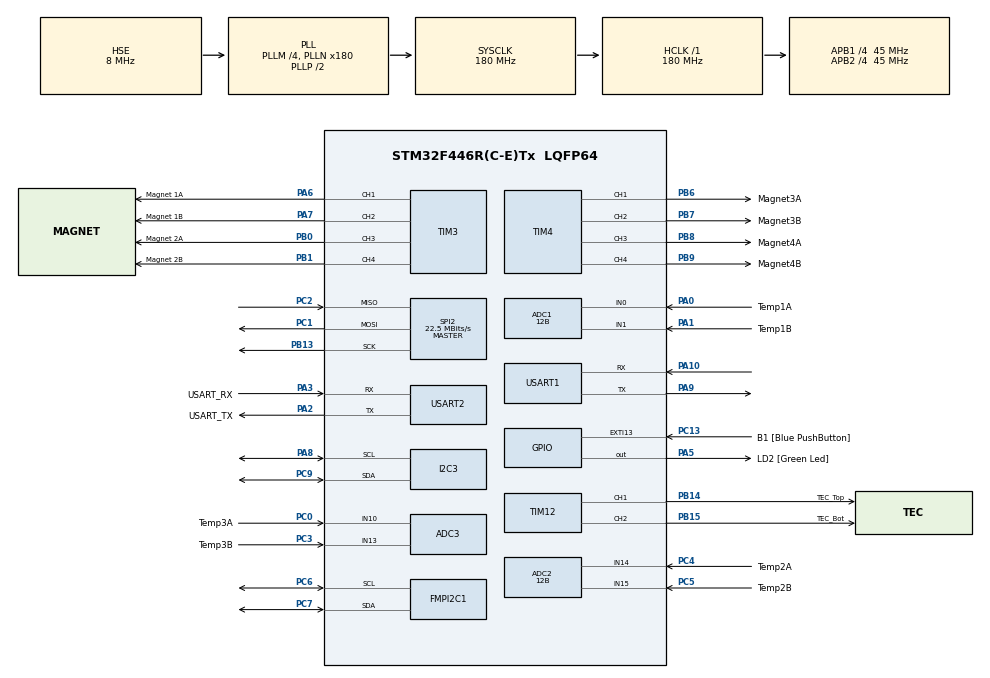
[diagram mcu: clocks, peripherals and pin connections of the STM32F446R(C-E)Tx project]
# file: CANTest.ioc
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ADC1.Channel-0\#ChannelRegularConversion=ADC_CHANNEL_0
ADC1.Channel-1\#ChannelRegularConversion=ADC_CHANNEL_1
ADC1.Channel-2\#ChannelInjectedConversion=ADC_CHANNEL_0
ADC1.Channel-3\#ChannelInjectedConversion=ADC_CHANNEL_0
ADC1.ClockPrescaler=ADC_CLOCK_SYNC_PCLK_DIV6
ADC1.ContinuousConvMode=ENABLE
ADC1.DMAContinuousRequests=ENABLE
ADC1.DataAlign=ADC_DATAALIGN_RIGHT
ADC1.DiscontinuousConvMode=DISABLE
ADC1.EOCSelection=ADC_EOC_SEQ_CONV
ADC1.EnableAnalogWatchDog=false
ADC1.ExternalTrigConv=ADC_SOFTWARE_START
ADC1.ExternalTrigConvEdge=ADC_EXTERNALTRIGCONVEDGE_NONE
ADC1.InjNumberOfConversion=0
ADC1.InjectedOffset-2\#ChannelInjectedConversion=0
ADC1.InjectedOffset-3\#ChannelInjectedConversion=0
ADC1.NbrOfConversion=2
ADC1.NbrOfConversionFlag=1
ADC1.Rank-0\#ChannelRegularConversion=1
ADC1.Rank-1\#ChannelRegularConversion=2
ADC1.Rank-2\#ChannelInjectedConversion=1
ADC1.Rank-3\#ChannelInjectedConversion=2
ADC1.Resolution=ADC_RESOLUTION_12B
ADC1.SamplingTime-0\#ChannelRegularConversion=ADC_SAMPLETIME_15CYCLES
ADC1.SamplingTime-1\#ChannelRegularConversion=ADC_SAMPLETIME_15CYCLES
ADC1.SamplingTime-2\#ChannelInjectedConversion=ADC_SAMPLETIME_3CYCLES
ADC1.SamplingTime-3\#ChannelInjectedConversion=ADC_SAMPLETIME_3CYCLES
ADC1.ScanConvMode=ENABLE
ADC1.master=1
ADC2.Channel-0\#ChannelRegularConversion=ADC_CHANNEL_15
ADC2.ClockPrescaler=ADC_CLOCK_SYNC_PCLK_DIV6
ADC2.ContinuousConvMode=DISABLE
ADC2.DMAContinuousRequests=DISABLE
ADC2.DataAlign=ADC_DATAALIGN_RIGHT
ADC2.DiscontinuousConvMode=DISABLE
ADC2.EOCSelection=ADC_EOC_SINGLE_CONV
ADC2.EnableAnalogWatchDog=false
ADC2.ExternalTrigConv=ADC_SOFTWARE_START
ADC2.ExternalTrigConvEdge=ADC_EXTERNALTRIGCONVEDGE_NONE
ADC2.InjNumberOfConversion=0
ADC2.NbrOfConversion=1
ADC2.NbrOfConversionFlag=1
ADC2.Rank-0\#ChannelRegularConversion=1
ADC2.Resolution=ADC_RESOLUTION_12B
ADC2.SamplingTime-0\#ChannelRegularConversion=ADC_SAMPLETIME_3CYCLES
ADC2.ScanConvMode=DISABLE
ADC3.Channel-4\#ChannelRegularConversion=ADC_CHANNEL_10
ADC3.ClockPrescaler=ADC_CLOCK_SYNC_PCLK_DIV6
ADC3.NbrOfConversionFlag=1
ADC3.Rank-4\#ChannelRegularConversion=1
ADC3.SamplingTime-4\#ChannelRegularConversion=ADC_SAMPLETIME_3CYCLES
Dma.ADC1.0.Direction=DMA_PERIPH_TO_MEMORY
Dma.ADC1.0.FIFOMode=DMA_FIFOMODE_DISABLE
Dma.ADC1.0.Instance=DMA2_Stream0
Dma.ADC1.0.MemDataAlignment=DMA_MDATAALIGN_HALFWORD
Dma.ADC1.0.MemInc=DMA_MINC_ENABLE
Dma.ADC1.0.Mode=DMA_CIRCULAR
Dma.ADC1.0.PeriphDataAlignment=DMA_PDATAALIGN_HALFWORD
Dma.ADC1.0.PeriphInc=DMA_PINC_DISABLE
Dma.ADC1.0.Priority=DMA_PRIORITY_VERY_HIGH
Dma.Request0=ADC1
FREERTOS.Tasks01=defaultTask,0,128,StartDefaultTask,Default,NULL,Dynamic,NULL,NULL;dataLogTask,-3,128,StartDataLogTask,Default,NULL,Dynamic,NULL,NULL;tempSenseTask,-3,128,StartTempSenseTask,Default,NULL,Dynamic,NULL,NULL;magnetSetTask,-3,128,StartMagnetSetTask,Default,NULL,Dynamic,NULL,NULL
FREERTOS.configCHECK_FOR_STACK_OVERFLOW=2
FREERTOS.configGENERATE_RUN_TIME_STATS=1
FREERTOS.configUSE_TIMERS=1
Mcu.Family=STM32F4
Mcu.Name=STM32F446R(C-E)Tx
Mcu.Package=LQFP64
NVIC.DMA2_Stream0_IRQn=true\:5\:0\:false\:false\:true\:true\:false
NVIC.PriorityGroup=NVIC_PRIORITYGROUP_4
PA0-WKUP.GPIO_Label=Temp1A
PA0-WKUP.Signal=ADCx_IN0
PA1.GPIO_Label=Temp1B
PA1.Signal=ADCx_IN1
PA10.Mode=Asynchronous
PA10.Signal=USART1_RX
PA13.GPIO_Label=TMS
PA13.Signal=SYS_JTMS-SWDIO
PA14.GPIO_Label=TCK
PA14.Signal=SYS_JTCK-SWCLK
PA2.GPIO_Label=USART_TX
PA2.Mode=Asynchronous
PA2.Signal=USART2_TX
PA3.GPIO_Label=USART_RX
PA3.Mode=Asynchronous
PA3.Signal=USART2_RX
PA5.GPIO_Label=LD2 [Green Led]
PA5.Signal=GPIO_Output
PA6.GPIO_Label=Magnet 1A
PA6.Signal=S_TIM3_CH1
PA7.GPIO_Label=Magnet 1B
PA7.Signal=S_TIM3_CH2
PA8.Mode=I2C
PA8.Signal=I2C3_SCL
PA9.Mode=Asynchronous
PA9.Signal=USART1_TX
PB0.GPIO_Label=Magnet 2A
PB0.Signal=S_TIM3_CH3
PB1.GPIO_Label=Magnet 2B
PB1.Signal=S_TIM3_CH4
PB13.Mode=Full_Duplex_Master
PB13.Signal=SPI2_SCK
PB14.GPIO_Label=TEC_Top
PB14.Signal=S_TIM12_CH1
PB15.GPIO_Label=TEC_Bot
PB15.Signal=S_TIM12_CH2
PB3.GPIO_Label=SWO
PB3.Signal=SYS_JTDO-SWO
PB6.GPIO_Label=Magnet3A
PB6.Signal=S_TIM4_CH1
PB7.GPIO_Label=Magnet3B
PB7.GPIO_Speed=GPIO_SPEED_FREQ_LOW
PB7.Signal=S_TIM4_CH2
PB8.GPIO_Label=Magnet4A
PB8.GPIO_Speed=GPIO_SPEED_FREQ_LOW
PB8.Signal=S_TIM4_CH3
PB9.GPIO_Label=Magnet4B
PB9.GPIO_Speed=GPIO_SPEED_FREQ_LOW
PB9.Signal=S_TIM4_CH4
PC0.GPIO_Label=Temp3A
PC0.Signal=ADCx_IN10
PC1.Mode=Full_Duplex_Master
PC1.Signal=SPI2_MOSI
PC13.GPIO_Label=B1 [Blue PushButton]
PC13.GPIO_ModeDefaultEXTI=GPIO_MODE_EVT_RISING
PC13.Signal=GPXTI13
PC14-OSC32_IN.Mode=LSE-External-Oscillator
PC14-OSC32_IN.Signal=RCC_OSC32_IN
PC15-OSC32_OUT.Mode=LSE-External-Oscillator
PC15-OSC32_OUT.Signal=RCC_OSC32_OUT
PC2.Mode=Full_Duplex_Master
PC2.Signal=SPI2_MISO
PC3.GPIO_Label=Temp3B
PC3.Signal=ADCx_IN13
PC4.GPIO_Label=Temp2A
PC4.Signal=ADCx_IN14
PC5.GPIO_Label=Temp2B
PC5.Signal=ADCx_IN15
PC6.Mode=I2C
PC6.Signal=FMPI2C1_SCL
PC7.Mode=I2C
PC7.Signal=FMPI2C1_SDA
PC9.Mode=I2C
PC9.Signal=I2C3_SDA
PH0-OSC_IN.Mode=HSE-External-Clock-Source
PH0-OSC_IN.Signal=RCC_OSC_IN
PH1-OSC_OUT.Mode=HSE-External-Clock-Source
PH1-OSC_OUT.Signal=RCC_OSC_OUT
ProjectManager.HeapSize=0x200
ProjectManager.StackSize=0x400
ProjectManager.TargetToolchain=SW4STM32
RCC.AHBFreq_Value=180000000
RCC.APB1CLKDivider=RCC_HCLK_DIV4
RCC.APB1Freq_Value=45000000
RCC.APB1TimFreq_Value=90000000
RCC.APB2CLKDivider=RCC_HCLK_DIV4
RCC.APB2Freq_Value=45000000
RCC.APB2TimFreq_Value=90000000
RCC.CortexFreq_Value=180000000
RCC.FLatency-AdvancedSettings=FLASH_LATENCY_5
RCC.HCLKFreq_Value=180000000
RCC.HSE_VALUE=8000000
RCC.HSI_VALUE=16000000
RCC.PLLM=4
RCC.PLLN=180
RCC.PLLSourceVirtual=RCC_PLLSOURCE_HSE
RCC.RCC_RTC_Clock_SourceVirtual=RCC_RTCCLKSOURCE_LSE
RCC.SYSCLKFreq_VALUE=180000000
RCC.SYSCLKSource=RCC_SYSCLKSOURCE_PLLCLK
RCC.USBFreq_Value=180000000
RCC.VCOOutputFreq_Value=360000000
RTC.Format=RTC_FORMAT_BIN
SH.ADCx_IN0.0=ADC1_IN0,IN0
SH.ADCx_IN1.0=ADC1_IN1,IN1
SH.ADCx_IN10.0=ADC3_IN10,IN10
SH.ADCx_IN13.0=ADC3_IN13,IN13
SH.ADCx_IN14.0=ADC2_IN14,IN14
SH.ADCx_IN15.0=ADC2_IN15,IN15
SH.S_TIM12_CH1.0=TIM12_CH1,PWM Generation1 CH1
SH.S_TIM12_CH2.0=TIM12_CH2,PWM Generation2 CH2
SH.S_TIM3_CH1.0=TIM3_CH1,Output Compare1 CH1
SH.S_TIM3_CH2.0=TIM3_CH2,Output Compare2 CH2
SH.S_TIM3_CH3.0=TIM3_CH3,Output Compare3 CH3
SH.S_TIM3_CH4.0=TIM3_CH4,Output Compare4 CH4
SH.S_TIM4_CH1.0=TIM4_CH1,Output Compare1 CH1
SH.S_TIM4_CH2.0=TIM4_CH2,Output Compare2 CH2
SH.S_TIM4_CH3.0=TIM4_CH3,Output Compare3 CH3
SH.S_TIM4_CH4.0=TIM4_CH4,Output Compare4 CH4
SPI2.BaudRatePrescaler=SPI_BAUDRATEPRESCALER_2
SPI2.CalculateBaudRate=22.5 MBits/s
SPI2.Direction=SPI_DIRECTION_2LINES
SPI2.Mode=SPI_MODE_MASTER
SPI2.VirtualType=VM_MASTER
TIM12.Channel-PWM\ Generation1\ CH1=TIM_CHANNEL_1
TIM12.Channel-PWM\ Generation2\ CH2=TIM_CHANNEL_2
TIM3.Channel-Output\ Compare1\ CH1=TIM_CHANNEL_1
TIM3.Channel-Output\ Compare2\ CH2=TIM_CHANNEL_2
TIM3.Channel-Output\ Compare3\ CH3=TIM_CHANNEL_3
TIM3.Channel-Output\ Compare4\ CH4=TIM_CHANNEL_4
TIM3.OCMode_1=TIM_OCMODE_ACTIVE
TIM3.OCMode_2=TIM_OCMODE_ACTIVE
TIM3.OCMode_3=TIM_OCMODE_ACTIVE
TIM3.OCMode_4=TIM_OCMODE_ACTIVE
TIM3.TIM_MasterSlaveMode=TIM_MASTERSLAVEMODE_ENABLE
TIM4.Channel-Output\ Compare1\ CH1=TIM_CHANNEL_1
TIM4.Channel-Output\ Compare2\ CH2=TIM_CHANNEL_2
TIM4.Channel-Output\ Compare3\ CH3=TIM_CHANNEL_3
TIM4.Channel-Output\ Compare4\ CH4=TIM_CHANNEL_4
TIM4.OCMode_1=TIM_OCMODE_ACTIVE
TIM4.OCMode_2=TIM_OCMODE_ACTIVE
TIM4.OCMode_3=TIM_OCMODE_ACTIVE
TIM4.OCMode_4=TIM_OCMODE_ACTIVE
TIM4.TIM_MasterSlaveMode=TIM_MASTERSLAVEMODE_ENABLE
USART1.VirtualMode=VM_ASYNC
USART2.VirtualMode=VM_ASYNC
VP_FREERTOS_VS_ENABLE.Mode=Enabled
VP_RTC_VS_RTC_Activate.Mode=RTC_Enabled
VP_RTC_VS_RTC_Calendar.Mode=RTC_Calendar
VP_WWDG_VS_WWDG.Mode=WWDG_Activate
board=NUCLEO-F446RE

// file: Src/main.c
/**
  ******************************************************************************
  * File Name          : main.c
  * Description        : Main program body
  ******************************************************************************
  * This notice applies to any and all portions of this file
  * that are not between comment pairs USER CODE BEGIN and
  * USER CODE END. Other portions of this file, whether
  * inserted by the user or by software development tools
  * are owned by their respective copyright owners.
  *
  * Copyright (c) 2017 STMicroelectronics International N.V.
  * All rights reserved.
  *
  * Redistribution and use in source and binary forms, with or without
  * modification, are permitted, provided that the following conditions are met:
  *
  * 1. Redistribution of source code must retain the above copyright notice,
  *    this list of conditions and the following disclaimer.
  * 2. Redistributions in binary form must reproduce the above copyright notice,
  *    this list of conditions and the following disclaimer in the documentation
  *    and/or other materials provided with the distribution.
  * 3. Neither the name of STMicroelectronics nor the names of other
  *    contributors to this software may be used to endorse or promote products
  *    derived from this software without specific written permission.
  * 4. This software, including modifications and/or derivative works of this
  *    software, must execute solely and exclusively on microcontroller or
  *    microprocessor devices manufactured by or for STMicroelectronics.
  * 5. Redistribution and use of this software other than as permitted under
  *    this license is void and will automatically terminate your rights under
  *    this license.
  *
  * THIS SOFTWARE IS PROVIDED BY STMICROELECTRONICS AND CONTRIBUTORS "AS IS"
  * AND ANY EXPRESS, IMPLIED OR STATUTORY WARRANTIES, INCLUDING, BUT NOT
  * LIMITED TO, THE IMPLIED WARRANTIES OF MERCHANTABILITY, FITNESS FOR A
  * PARTICULAR PURPOSE AND NON-INFRINGEMENT OF THIRD PARTY INTELLECTUAL PROPERTY
  * RIGHTS ARE DISCLAIMED TO THE FULLEST EXTENT PERMITTED BY LAW. IN NO EVENT
  * SHALL STMICROELECTRONICS OR CONTRIBUTORS BE LIABLE FOR ANY DIRECT, INDIRECT,
  * INCIDENTAL, SPECIAL, EXEMPLARY, OR CONSEQUENTIAL DAMAGES (INCLUDING, BUT NOT
  * LIMITED TO, PROCUREMENT OF SUBSTITUTE GOODS OR SERVICES; LOSS OF USE, DATA,
  * OR PROFITS; OR BUSINESS INTERRUPTION) HOWEVER CAUSED AND ON ANY THEORY OF
  * LIABILITY, WHETHER IN CONTRACT, STRICT LIABILITY, OR TORT (INCLUDING
  * NEGLIGENCE OR OTHERWISE) ARISING IN ANY WAY OUT OF THE USE OF THIS SOFTWARE,
  * EVEN IF ADVISED OF THE POSSIBILITY OF SUCH DAMAGE.
  *
  ******************************************************************************
  */

#include "main.h"
#include "stm32f4xx_hal.h"
#include "cmsis_os.h"

ADC_HandleTypeDef hadc1;
ADC_HandleTypeDef hadc2;
ADC_HandleTypeDef hadc3;

FMPI2C_HandleTypeDef hfmpi2c1;

I2C_HandleTypeDef hi2c3;

RTC_HandleTypeDef hrtc;
RTC_TimeTypeDef sTime;
RTC_DateTypeDef sDate;

SPI_HandleTypeDef hspi2;

TIM_HandleTypeDef htim3;
TIM_HandleTypeDef htim4;
TIM_HandleTypeDef htim12;

UART_HandleTypeDef huart1;
UART_HandleTypeDef huart2;

WWDG_HandleTypeDef hwwdg;

osThreadId defaultTaskHandle;
osThreadId dataLogTaskHandle;
osThreadId tempSenseTaskHandle;
osThreadId magnetSetTaskHandle;

/* USER CODE BEGIN PV */
/* Private variables ---------------------------------------------------------*/

/* USER CODE END PV */

void SystemClock_Config(void);
static void MX_GPIO_Init(void);
static void MX_ADC1_Init(void);
static void MX_ADC2_Init(void);
static void MX_ADC3_Init(void);
static void MX_FMPI2C1_Init(void);
static void MX_I2C3_Init(void);
static void MX_RTC_Init(void);
static void MX_SPI2_Init(void);
static void MX_TIM3_Init(void);
static void MX_TIM4_Init(void);
static void MX_TIM12_Init(void);
static void MX_USART1_UART_Init(void);
static void MX_USART2_UART_Init(void);
static void MX_WWDG_Init(void);
void StartDefaultTask(void const * argument);
void StartDataLogTask(void const * argument);
void StartTempSenseTask(void const * argument);
void StartMagnetSetTask(void const * argument);

void HAL_TIM_MspPostInit(TIM_HandleTypeDef *htim);

/* USER CODE BEGIN PFP */
/* Private function prototypes -----------------------------------------------*/

/* USER CODE END PFP */

int main(void)
{

  /* USER CODE BEGIN 1 */
  int i_hello_user;
  /* USER CODE END 1 */

  /* MCU Configuration----------------------------------------------------------*/

  /* Reset of all peripherals, Initializes the Flash interface and the Systick. */
  HAL_Init();

  /* Configure the system clock */
  SystemClock_Config();

  /* Initialize all configured peripherals */
  MX_GPIO_Init();
  MX_ADC1_Init();
  MX_ADC2_Init();
  MX_ADC3_Init();
  MX_FMPI2C1_Init();
  MX_I2C3_Init();
  MX_RTC_Init();
  MX_SPI2_Init();
  MX_TIM3_Init();
  MX_TIM4_Init();
  MX_TIM12_Init();
  MX_USART1_UART_Init();
  MX_USART2_UART_Init();
  MX_WWDG_Init();

  /* Create the thread(s) */
  /* definition and creation of defaultTask */
  osThreadDef(defaultTask, StartDefaultTask, osPriorityNormal, 0, 128);
  defaultTaskHandle = osThreadCreate(osThread(defaultTask), NULL);

  /* definition and creation of dataLogTask */
  osThreadDef(dataLogTask, StartDataLogTask, osPriorityIdle, 0, 128);
  dataLogTaskHandle = osThreadCreate(osThread(dataLogTask), NULL);

  /* definition and creation of tempSenseTask */
  osThreadDef(tempSenseTask, StartTempSenseTask, osPriorityIdle, 0, 128);
  tempSenseTaskHandle = osThreadCreate(osThread(tempSenseTask), NULL);

  /* definition and creation of magnetSetTask */
  osThreadDef(magnetSetTask, StartMagnetSetTask, osPriorityIdle, 0, 128);
  magnetSetTaskHandle = osThreadCreate(osThread(magnetSetTask), NULL);

  /* Start scheduler */
  osKernelStart();

  /* We should never get here as control is now taken by the scheduler */

  /* Infinite loop */
  while (1)
  {

  }

}

/** System Clock Configuration
*/
void SystemClock_Config(void)
{

  RCC_OscInitTypeDef RCC_OscInitStruct;
  RCC_ClkInitTypeDef RCC_ClkInitStruct;
  RCC_PeriphCLKInitTypeDef PeriphClkInitStruct;

    /**Configure the main internal regulator output voltage
    */
  __HAL_RCC_PWR_CLK_ENABLE();

  __HAL_PWR_VOLTAGESCALING_CONFIG(PWR_REGULATOR_VOLTAGE_SCALE1);

    /**Initializes the CPU, AHB and APB busses clocks
    */
  RCC_OscInitStruct.OscillatorType = RCC_OSCILLATORTYPE_HSE|RCC_OSCILLATORTYPE_LSE;
  RCC_OscInitStruct.HSEState = RCC_HSE_BYPASS;
  RCC_OscInitStruct.LSEState = RCC_LSE_ON;
  RCC_OscInitStruct.PLL.PLLState = RCC_PLL_ON;
  RCC_OscInitStruct.PLL.PLLSource = RCC_PLLSOURCE_HSE;
  RCC_OscInitStruct.PLL.PLLM = 4;
  RCC_OscInitStruct.PLL.PLLN = 180;
  RCC_OscInitStruct.PLL.PLLP = RCC_PLLP_DIV2;
  RCC_OscInitStruct.PLL.PLLQ = 2;
  RCC_OscInitStruct.PLL.PLLR = 2;
  if (HAL_RCC_OscConfig(&RCC_OscInitStruct) != HAL_OK)
  {
    _Error_Handler(__FILE__, __LINE__);
  }

    /**Activate the Over-Drive mode
    */
  if (HAL_PWREx_EnableOverDrive() != HAL_OK)
  {
    _Error_Handler(__FILE__, __LINE__);
  }

    /**Initializes the CPU, AHB and APB busses clocks
    */
  RCC_ClkInitStruct.ClockType = RCC_CLOCKTYPE_HCLK|RCC_CLOCKTYPE_SYSCLK
                              |RCC_CLOCKTYPE_PCLK1|RCC_CLOCKTYPE_PCLK2;
  RCC_ClkInitStruct.SYSCLKSource = RCC_SYSCLKSOURCE_PLLCLK;
  RCC_ClkInitStruct.AHBCLKDivider = RCC_SYSCLK_DIV1;
  RCC_ClkInitStruct.APB1CLKDivider = RCC_HCLK_DIV4;
  RCC_ClkInitStruct.APB2CLKDivider = RCC_HCLK_DIV4;

  if (HAL_RCC_ClockConfig(&RCC_ClkInitStruct, FLASH_LATENCY_5) != HAL_OK)
  {
    _Error_Handler(__FILE__, __LINE__);
  }

  PeriphClkInitStruct.PeriphClockSelection = RCC_PERIPHCLK_RTC|RCC_PERIPHCLK_FMPI2C1;
  PeriphClkInitStruct.RTCClockSelection = RCC_RTCCLKSOURCE_LSE;
  PeriphClkInitStruct.Fmpi2c1ClockSelection = RCC_FMPI2C1CLKSOURCE_APB;
  if (HAL_RCCEx_PeriphCLKConfig(&PeriphClkInitStruct) != HAL_OK)
  {
    _Error_Handler(__FILE__, __LINE__);
  }

    /**Configure the Systick interrupt time
    */
  HAL_SYSTICK_Config(HAL_RCC_GetHCLKFreq()/1000);

    /**Configure the Systick
    */
  HAL_SYSTICK_CLKSourceConfig(SYSTICK_CLKSOURCE_HCLK);

  /* SysTick_IRQn interrupt configuration */
  HAL_NVIC_SetPriority(SysTick_IRQn, 15, 0);
}

/* ADC1 init function */
static void MX_ADC1_Init(void)
{

  ADC_ChannelConfTypeDef sConfig;

    /**Configure the global features of the ADC (Clock, Resolution, Data Alignment and number of conversion)
    */
  hadc1.Instance = ADC1;
  hadc1.Init.ClockPrescaler = ADC_CLOCK_SYNC_PCLK_DIV2;
  hadc1.Init.Resolution = ADC_RESOLUTION_12B;
  hadc1.Init.ScanConvMode = DISABLE;
  hadc1.Init.ContinuousConvMode = DISABLE;
  hadc1.Init.DiscontinuousConvMode = DISABLE;
  hadc1.Init.ExternalTrigConvEdge = ADC_EXTERNALTRIGCONVEDGE_NONE;
  hadc1.Init.ExternalTrigConv = ADC_SOFTWARE_START;
  hadc1.Init.DataAlign = ADC_DATAALIGN_RIGHT;
  hadc1.Init.NbrOfConversion = 1;
  hadc1.Init.DMAContinuousRequests = DISABLE;
  hadc1.Init.EOCSelection = ADC_EOC_SINGLE_CONV;
  if (HAL_ADC_Init(&hadc1) != HAL_OK)
  {
    _Error_Handler(__FILE__, __LINE__);
  }

    /**Configure for the selected ADC regular channel its corresponding rank in the sequencer and its sample time.
    */
  sConfig.Channel = ADC_CHANNEL_0;
  sConfig.Rank = 1;
  sConfig.SamplingTime = ADC_SAMPLETIME_3CYCLES;
  if (HAL_ADC_ConfigChannel(&hadc1, &sConfig) != HAL_OK)
  {
    _Error_Handler(__FILE__, __LINE__);
  }

}

/* ADC2 init function */
static void MX_ADC2_Init(void)
{

  ADC_ChannelConfTypeDef sConfig;

    /**Configure the global features of the ADC (Clock, Resolution, Data Alignment and number of conversion)
    */
  hadc2.Instance = ADC2;
  hadc2.Init.ClockPrescaler = ADC_CLOCK_SYNC_PCLK_DIV2;
  hadc2.Init.Resolution = ADC_RESOLUTION_12B;
  hadc2.Init.ScanConvMode = DISABLE;
  hadc2.Init.ContinuousConvMode = DISABLE;
  hadc2.Init.DiscontinuousConvMode = DISABLE;
  hadc2.Init.ExternalTrigConvEdge = ADC_EXTERNALTRIGCONVEDGE_NONE;
  hadc2.Init.ExternalTrigConv = ADC_SOFTWARE_START;
  hadc2.Init.DataAlign = ADC_DATAALIGN_RIGHT;
  hadc2.Init.NbrOfConversion = 1;
  hadc2.Init.DMAContinuousRequests = DISABLE;
  hadc2.Init.EOCSelection = ADC_EOC_SINGLE_CONV;
  if (HAL_ADC_Init(&hadc2) != HAL_OK)
  {
    _Error_Handler(__FILE__, __LINE__);
  }

    /**Configure for the selected ADC regular channel its corresponding rank in the sequencer and its sample time.
    */
  sConfig.Channel = ADC_CHANNEL_15;
  sConfig.Rank = 1;
  sConfig.SamplingTime = ADC_SAMPLETIME_3CYCLES;
  if (HAL_ADC_ConfigChannel(&hadc2, &sConfig) != HAL_OK)
  {
    _Error_Handler(__FILE__, __LINE__);
  }

}

/* ADC3 init function */
static void MX_ADC3_Init(void)
{

  ADC_ChannelConfTypeDef sConfig;

    /**Configure the global features of the ADC (Clock, Resolution, Data Alignment and number of conversion)
    */
  hadc3.Instance = ADC3;
  hadc3.Init.ClockPrescaler = ADC_CLOCK_SYNC_PCLK_DIV2;
  hadc3.Init.Resolution = ADC_RESOLUTION_12B;
  hadc3.Init.ScanConvMode = DISABLE;
  hadc3.Init.ContinuousConvMode = DISABLE;
  hadc3.Init.DiscontinuousConvMode = DISABLE;
  hadc3.Init.ExternalTrigConvEdge = ADC_EXTERNALTRIGCONVEDGE_NONE;
  hadc3.Init.ExternalTrigConv = ADC_SOFTWARE_START;
  hadc3.Init.DataAlign = ADC_DATAALIGN_RIGHT;
  hadc3.Init.NbrOfConversion = 1;
  hadc3.Init.DMAContinuousRequests = DISABLE;
  hadc3.Init.EOCSelection = ADC_EOC_SINGLE_CONV;
  if (HAL_ADC_Init(&hadc3) != HAL_OK)
  {
    _Error_Handler(__FILE__, __LINE__);
  }

    /**Configure for the selected ADC regular channel its corresponding rank in the sequencer and its sample time.
    */
  sConfig.Channel = ADC_CHANNEL_10;
  sConfig.Rank = 1;
  sConfig.SamplingTime = ADC_SAMPLETIME_3CYCLES;
  if (HAL_ADC_ConfigChannel(&hadc3, &sConfig) != HAL_OK)
  {
    _Error_Handler(__FILE__, __LINE__);
  }

}

/* FMPI2C1 init function */
static void MX_FMPI2C1_Init(void)
{

  hfmpi2c1.Instance = FMPI2C1;
  hfmpi2c1.Init.Timing = 0x2000090E;
  hfmpi2c1.Init.OwnAddress1 = 0;
  hfmpi2c1.Init.AddressingMode = FMPI2C_ADDRESSINGMODE_7BIT;
  hfmpi2c1.Init.DualAddressMode = FMPI2C_DUALADDRESS_DISABLE;
  hfmpi2c1.Init.OwnAddress2 = 0;
  hfmpi2c1.Init.OwnAddress2Masks = FMPI2C_OA2_NOMASK;
  hfmpi2c1.Init.GeneralCallMode = FMPI2C_GENERALCALL_DISABLE;
  hfmpi2c1.Init.NoStretchMode = FMPI2C_NOSTRETCH_DISABLE;
  if (HAL_FMPI2C_Init(&hfmpi2c1) != HAL_OK)
  {
    _Error_Handler(__FILE__, __LINE__);
  }

    /**Configure Analogue filter
    */
  if (HAL_FMPI2CEx_ConfigAnalogFilter(&hfmpi2c1, FMPI2C_ANALOGFILTER_ENABLE) != HAL_OK)
  {
    _Error_Handler(__FILE__, __LINE__);
  }

}

/* I2C3 init function */
static void MX_I2C3_Init(void)
{

  hi2c3.Instance = I2C3;
  hi2c3.Init.ClockSpeed = 100000;
  hi2c3.Init.DutyCycle = I2C_DUTYCYCLE_2;
  hi2c3.Init.OwnAddress1 = 0;
  hi2c3.Init.AddressingMode = I2C_ADDRESSINGMODE_7BIT;
  hi2c3.Init.DualAddressMode = I2C_DUALADDRESS_DISABLE;
  hi2c3.Init.OwnAddress2 = 0;
  hi2c3.Init.GeneralCallMode = I2C_GENERALCALL_DISABLE;
  hi2c3.Init.NoStretchMode = I2C_NOSTRETCH_DISABLE;
  if (HAL_I2C_Init(&hi2c3) != HAL_OK)
  {
    _Error_Handler(__FILE__, __LINE__);
  }

}

/* RTC init function */
static void MX_RTC_Init(void)
{

    /**Initialize RTC Only
    */
  hrtc.Instance = RTC;
  hrtc.Init.HourFormat = RTC_HOURFORMAT_24;
  hrtc.Init.AsynchPrediv = 127;
  hrtc.Init.SynchPrediv = 255;
  hrtc.Init.OutPut = RTC_OUTPUT_DISABLE;
  hrtc.Init.OutPutPolarity = RTC_OUTPUT_POLARITY_HIGH;
  hrtc.Init.OutPutType = RTC_OUTPUT_TYPE_OPENDRAIN;
  if (HAL_RTC_Init(&hrtc) != HAL_OK)
  {
    _Error_Handler(__FILE__, __LINE__);
  }

    /**Initialize RTC and set the Time and Date
    */
  if(HAL_RTCEx_BKUPRead(&hrtc, RTC_BKP_DR0) != 0x32F2){
  if (HAL_RTC_SetTime(&hrtc, &sTime, RTC_FORMAT_BIN) != HAL_OK)
  {
    _Error_Handler(__FILE__, __LINE__);
  }

  if (HAL_RTC_SetDate(&hrtc, &sDate, RTC_FORMAT_BIN) != HAL_OK)
  {
    _Error_Handler(__FILE__, __LINE__);
  }

    HAL_RTCEx_BKUPWrite(&hrtc,RTC_BKP_DR0,0x32F2);
  }

}

/* SPI2 init function */
static void MX_SPI2_Init(void)
{

  /* SPI2 parameter configuration*/
  hspi2.Instance = SPI2;
  hspi2.Init.Mode = SPI_MODE_MASTER;
  hspi2.Init.Direction = SPI_DIRECTION_2LINES;
  hspi2.Init.DataSize = SPI_DATASIZE_8BIT;
  hspi2.Init.CLKPolarity = SPI_POLARITY_LOW;
  hspi2.Init.CLKPhase = SPI_PHASE_1EDGE;
  hspi2.Init.NSS = SPI_NSS_SOFT;
  hspi2.Init.BaudRatePrescaler = SPI_BAUDRATEPRESCALER_2;
  hspi2.Init.FirstBit = SPI_FIRSTBIT_MSB;
  hspi2.Init.TIMode = SPI_TIMODE_DISABLE;
  hspi2.Init.CRCCalculation = SPI_CRCCALCULATION_DISABLE;
  hspi2.Init.CRCPolynomial = 10;
  if (HAL_SPI_Init(&hspi2) != HAL_OK)
  {
    _Error_Handler(__FILE__, __LINE__);
  }

}

/* TIM3 init function */
static void MX_TIM3_Init(void)
{

  TIM_MasterConfigTypeDef sMasterConfig;
  TIM_OC_InitTypeDef sConfigOC;

  htim3.Instance = TIM3;
  htim3.Init.Prescaler = 0;
  htim3.Init.CounterMode = TIM_COUNTERMODE_UP;
  htim3.Init.Period = 0;
  htim3.Init.ClockDivision = TIM_CLOCKDIVISION_DIV1;
  if (HAL_TIM_OC_Init(&htim3) != HAL_OK)
  {
    _Error_Handler(__FILE__, __LINE__);
  }

  sMasterConfig.MasterOutputTrigger = TIM_TRGO_RESET;
  sMasterConfig.MasterSlaveMode = TIM_MASTERSLAVEMODE_ENABLE;
  if (HAL_TIMEx_MasterConfigSynchronization(&htim3, &sMasterConfig) != HAL_OK)
  {
    _Error_Handler(__FILE__, __LINE__);
  }

  sConfigOC.OCMode = TIM_OCMODE_ACTIVE;
  sConfigOC.Pulse = 0;
  sConfigOC.OCPolarity = TIM_OCPOLARITY_HIGH;
  sConfigOC.OCFastMode = TIM_OCFAST_DISABLE;
  if (HAL_TIM_OC_ConfigChannel(&htim3, &sConfigOC, TIM_CHANNEL_1) != HAL_OK)
  {
    _Error_Handler(__FILE__, __LINE__);
  }

  if (HAL_TIM_OC_ConfigChannel(&htim3, &sConfigOC, TIM_CHANNEL_2) != HAL_OK)
  {
    _Error_Handler(__FILE__, __LINE__);
  }

  if (HAL_TIM_OC_ConfigChannel(&htim3, &sConfigOC, TIM_CHANNEL_3) != HAL_OK)
  {
    _Error_Handler(__FILE__, __LINE__);
  }

  if (HAL_TIM_OC_ConfigChannel(&htim3, &sConfigOC, TIM_CHANNEL_4) != HAL_OK)
  {
    _Error_Handler(__FILE__, __LINE__);
  }

  HAL_TIM_MspPostInit(&htim3);

}

/* TIM4 init function */
static void MX_TIM4_Init(void)
{

  TIM_MasterConfigTypeDef sMasterConfig;
  TIM_OC_InitTypeDef sConfigOC;

  htim4.Instance = TIM4;
  htim4.Init.Prescaler = 0;
  htim4.Init.CounterMode = TIM_COUNTERMODE_UP;
  htim4.Init.Period = 0;
  htim4.Init.ClockDivision = TIM_CLOCKDIVISION_DIV1;
  if (HAL_TIM_OC_Init(&htim4) != HAL_OK)
  {
    _Error_Handler(__FILE__, __LINE__);
  }

  sMasterConfig.MasterOutputTrigger = TIM_TRGO_RESET;
  sMasterConfig.MasterSlaveMode = TIM_MASTERSLAVEMODE_ENABLE;
  if (HAL_TIMEx_MasterConfigSynchronization(&htim4, &sMasterConfig) != HAL_OK)
  {
    _Error_Handler(__FILE__, __LINE__);
  }

  sConfigOC.OCMode = TIM_OCMODE_ACTIVE;
  sConfigOC.Pulse = 0;
  sConfigOC.OCPolarity = TIM_OCPOLARITY_HIGH;
  sConfigOC.OCFastMode = TIM_OCFAST_DISABLE;
  if (HAL_TIM_OC_ConfigChannel(&htim4, &sConfigOC, TIM_CHANNEL_1) != HAL_OK)
  {
    _Error_Handler(__FILE__, __LINE__);
  }

  if (HAL_TIM_OC_ConfigChannel(&htim4, &sConfigOC, TIM_CHANNEL_2) != HAL_OK)
  {
    _Error_Handler(__FILE__, __LINE__);
  }

  if (HAL_TIM_OC_ConfigChannel(&htim4, &sConfigOC, TIM_CHANNEL_3) != HAL_OK)
  {
    _Error_Handler(__FILE__, __LINE__);
  }

  if (HAL_TIM_OC_ConfigChannel(&htim4, &sConfigOC, TIM_CHANNEL_4) != HAL_OK)
  {
    _Error_Handler(__FILE__, __LINE__);
  }

  HAL_TIM_MspPostInit(&htim4);

}

/* TIM12 init function */
static void MX_TIM12_Init(void)
{

  TIM_OC_InitTypeDef sConfigOC;

  htim12.Instance = TIM12;
  htim12.Init.Prescaler = 0;
  htim12.Init.CounterMode = TIM_COUNTERMODE_UP;
  htim12.Init.Period = 0;
  htim12.Init.ClockDivision = TIM_CLOCKDIVISION_DIV1;
  if (HAL_TIM_PWM_Init(&htim12) != HAL_OK)
  {
    _Error_Handler(__FILE__, __LINE__);
  }

  sConfigOC.OCMode = TIM_OCMODE_PWM1;
  sConfigOC.Pulse = 0;
  sConfigOC.OCPolarity = TIM_OCPOLARITY_HIGH;
  sConfigOC.OCFastMode = TIM_OCFAST_DISABLE;
  if (HAL_TIM_PWM_ConfigChannel(&htim12, &sConfigOC, TIM_CHANNEL_1) != HAL_OK)
  {
    _Error_Handler(__FILE__, __LINE__);
  }

  if (HAL_TIM_PWM_ConfigChannel(&htim12, &sConfigOC, TIM_CHANNEL_2) != HAL_OK)
  {
    _Error_Handler(__FILE__, __LINE__);
  }

  HAL_TIM_MspPostInit(&htim12);

}

/* USART1 init function */
static void MX_USART1_UART_Init(void)
{

  huart1.Instance = USART1;
  huart1.Init.BaudRate = 115200;
  huart1.Init.WordLength = UART_WORDLENGTH_8B;
  huart1.Init.StopBits = UART_STOPBITS_1;
  huart1.Init.Parity = UART_PARITY_NONE;
  huart1.Init.Mode = UART_MODE_TX_RX;
  huart1.Init.HwFlowCtl = UART_HWCONTROL_NONE;
  huart1.Init.OverSampling = UART_OVERSAMPLING_16;
  if (HAL_UART_Init(&huart1) != HAL_OK)
  {
    _Error_Handler(__FILE__, __LINE__);
  }

}

/* USART2 init function */
static void MX_USART2_UART_Init(void)
{

  huart2.Instance = USART2;
  huart2.Init.BaudRate = 115200;
  huart2.Init.WordLength = UART_WORDLENGTH_8B;
  huart2.Init.StopBits = UART_STOPBITS_1;
  huart2.Init.Parity = UART_PARITY_NONE;
  huart2.Init.Mode = UART_MODE_TX_RX;
  huart2.Init.HwFlowCtl = UART_HWCONTROL_NONE;
  huart2.Init.OverSampling = UART_OVERSAMPLING_16;
  if (HAL_UART_Init(&huart2) != HAL_OK)
  {
    _Error_Handler(__FILE__, __LINE__);
  }

}

/* WWDG init function */
static void MX_WWDG_Init(void)
{

  hwwdg.Instance = WWDG;
  hwwdg.Init.Prescaler = WWDG_PRESCALER_1;
  hwwdg.Init.Window = 64;
  hwwdg.Init.Counter = 64;
  hwwdg.Init.EWIMode = WWDG_EWI_DISABLE;
  if (HAL_WWDG_Init(&hwwdg) != HAL_OK)
  {
    _Error_Handler(__FILE__, __LINE__);
  }

}

/** Configure pins as
        * Analog
        * Input
        * Output
        * EVENT_OUT
        * EXTI
*/
static void MX_GPIO_Init(void)
{

  GPIO_InitTypeDef GPIO_InitStruct;

  /* GPIO Ports Clock Enable */
  __HAL_RCC_GPIOC_CLK_ENABLE();
  __HAL_RCC_GPIOH_CLK_ENABLE();
  __HAL_RCC_GPIOA_CLK_ENABLE();
  __HAL_RCC_GPIOB_CLK_ENABLE();

  /*Configure GPIO pin Output Level */
  HAL_GPIO_WritePin(LD2_GPIO_Port, LD2_Pin, GPIO_PIN_RESET);

  /*Configure GPIO pin : B1_Pin */
  GPIO_InitStruct.Pin = B1_Pin;
  GPIO_InitStruct.Mode = GPIO_MODE_EVT_RISING;
  GPIO_InitStruct.Pull = GPIO_NOPULL;
  HAL_GPIO_Init(B1_GPIO_Port, &GPIO_InitStruct);

  /*Configure GPIO pin : LD2_Pin */
  GPIO_InitStruct.Pin = LD2_Pin;
  GPIO_InitStruct.Mode = GPIO_MODE_OUTPUT_PP;
  GPIO_InitStruct.Pull = GPIO_NOPULL;
  GPIO_InitStruct.Speed = GPIO_SPEED_FREQ_LOW;
  HAL_GPIO_Init(LD2_GPIO_Port, &GPIO_InitStruct);

}

/* StartDefaultTask function */
void StartDefaultTask(void const * argument)
{

  for(;;)
  {
    osDelay(1);
  }
}

/* StartDataLogTask function */
void StartDataLogTask(void const * argument)
{
  for(;;)
  {
    osDelay(1);
  }
}

/* StartTempSenseTask function */
void StartTempSenseTask(void const * argument)
{
  for(;;)
  {
    osDelay(1);
  }
}

/* StartMagnetSetTask function */
void StartMagnetSetTask(void const * argument)
{
  for(;;)
  {
    osDelay(1);
  }
}

void _Error_Handler(char * file, int line)
{
  while(1)
  {
  }
}

/************************ (C) COPYRIGHT STMicroelectronics *****END OF FILE****/
